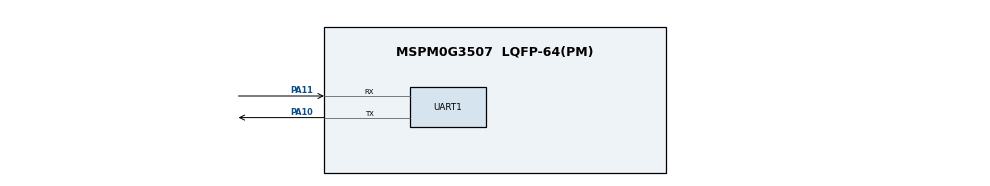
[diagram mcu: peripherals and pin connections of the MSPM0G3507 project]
/**
 * These arguments were used when this file was generated. They will be automatically applied on subsequent loads
 * via the GUI or CLI. Run CLI with '--help' for additional information on how to override these arguments.
 * @cliArgs --device "MSPM0G350X" --part "Default" --package "LQFP-64(PM)" --product "mspm0_sdk@2.10.00.04"
 * @v2CliArgs --device "MSPM0G3507" --package "LQFP-64(PM)" --product "mspm0_sdk@2.10.00.04"
 * @versions {"tool":"1.26.2+4477"}
 */

/**
 * Import the modules used in this configuration.
 * Note: I2C is handled by TI Drivers, NOT DriverLib syscfg.
 */
const GPIO   = scripting.addModule("/ti/driverlib/GPIO", {}, false);
const GPIO1  = GPIO.addInstance();
const GPIO2  = GPIO.addInstance();
const GPIO4  = GPIO.addInstance();
const GPIO5  = GPIO.addInstance();
const SYSCTL = scripting.addModule("/ti/driverlib/SYSCTL");
const UART   = scripting.addModule("/ti/driverlib/UART", {}, false);
const UART1  = UART.addInstance();

/**
 * Write custom configuration values to the imported modules.
 */
GPIO1.$name                              = "LED_BLUE";
GPIO1.port                               = "PORTB";
GPIO1.associatedPins[0].$name            = "PIN_BLUE";
GPIO1.associatedPins[0].direction        = "OUTPUT";
GPIO1.associatedPins[0].internalResistor = "PULL_DOWN";
GPIO1.associatedPins[0].initialValue     = "CLEARED";
GPIO1.associatedPins[0].assignedPin      = "3";

GPIO5.$name                              = "LED_GREEN";
GPIO5.port                               = "PORTB";
GPIO5.associatedPins[0].$name            = "PIN_GREEN";
GPIO5.associatedPins[0].direction        = "OUTPUT";
GPIO5.associatedPins[0].internalResistor = "PULL_DOWN";
GPIO5.associatedPins[0].initialValue     = "CLEARED";
GPIO5.associatedPins[0].assignedPin      = "2";

const Board = scripting.addModule("/ti/driverlib/Board", {}, false);

GPIO2.$name                              = "KEY";
GPIO2.port                               = "PORTA";
GPIO2.associatedPins[0].$name            = "PIN_18";
GPIO2.associatedPins[0].direction        = "INPUT";
GPIO2.associatedPins[0].internalResistor = "PULL_DOWN";
GPIO2.associatedPins[0].assignedPin      = "18";

GPIO4.$name                              = "MOTOR_I2C";
GPIO4.port                               = "PORTA";
GPIO4.associatedPins.create(2);
GPIO4.associatedPins[0].$name            = "SCL";
GPIO4.associatedPins[0].direction        = "OUTPUT";
GPIO4.associatedPins[0].internalResistor = "PULL_UP";
GPIO4.associatedPins[0].initialValue     = "SET";
GPIO4.associatedPins[0].assignedPin      = "15";   /* PA15 = SCL */
GPIO4.associatedPins[1].$name            = "SDA";
GPIO4.associatedPins[1].direction        = "OUTPUT";
GPIO4.associatedPins[1].internalResistor = "PULL_UP";
GPIO4.associatedPins[1].initialValue     = "SET";
GPIO4.associatedPins[1].assignedPin      = "16";   /* PA16 = SDA */

SYSCTL.forceDefaultClkConfig = true;
SYSCTL.clockTreeEn           = true;

UART1.$name                    = "UART_0";
UART1.enableFIFO               = true;
UART1.enableDMARX              = false;
UART1.enableDMATX              = true;
UART1.enabledDMATXTriggers     = "DL_UART_DMA_INTERRUPT_TX";
UART1.targetBaudRate           = 115200;
UART1.enableInternalLoopback   = false;
UART1.rxFifoThreshold          = "DL_UART_RX_FIFO_LEVEL_1_2_FULL";
UART1.peripheral.$assign       = "UART0";
UART1.peripheral.rxPin.$assign = "PA11";
UART1.peripheral.txPin.$assign = "PA10";
UART1.DMA_CHANNEL_TX.peripheral.$assign = "DMA_CH0";
UART1.DMA_CHANNEL_TX.addressMode        = "b2f";
UART1.DMA_CHANNEL_TX.srcIncDec          = "INCREMENT";
UART1.DMA_CHANNEL_TX.dstLength          = "BYTE";
UART1.DMA_CHANNEL_TX.srcLength          = "BYTE";
